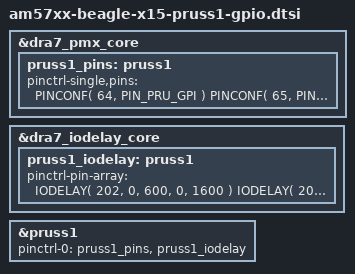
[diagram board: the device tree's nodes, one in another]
#include "dra7-pin-convenience.h"

&dra7_pmx_core {
	pruss1_pins: pruss1 {
		pinctrl-single,pins = <
			PINCONF(  64, PIN_PRU_GPI )  // P19.52 core 0 gpi  0
			PINCONF(  65, PIN_PRU_GPI )  // P19.45 core 0 gpi  1
			PINCONF(  66, PIN_PRU_GPI )  // P19.48 core 0 gpi  2
			PINCONF(  67, PIN_PRU_GPI )  // P19.53 core 0 gpi  3
			PINCONF(  68, PIN_PRU_GPI )  // P19.14 core 0 gpi  4
			PINCONF(  69, PIN_PRU_GPI )  // P19.15 core 0 gpi  5
			PINCONF(  71, PIN_PRU_GPI )  // P19.46 core 0 gpi  7
			PINCONF(  72, PIN_PRU_GPI )  // P19.49 core 0 gpi  8
			PINCONF(  73, PIN_PRU_GPI )  // P19.42 core 0 gpi  9
			PINCONF(  75, PIN_PRU_GPI )  // P19.43 core 0 gpi 11
			PINCONF(  77, PIN_PRU_GPI )  // P19.11 core 0 gpi 13
			PINCONF(  80, PIN_PRU_GPI )  // P19.39 core 0 gpi 16
			PINCONF(  81, PIN_PRU_GPI )  // P19.12 core 0 gpi 17
			PINCONF(  83, PIN_PRU_GPI )  // P19.40 core 0 gpi 19

			PINCONF(  93, PIN_PRU_GPI )  // P18.42 core 1 gpi  0
			PINCONF(  94, PIN_PRU_GPI )  // P18.13 core 1 gpi  1
			PINCONF(  95, PIN_PRU_GPI )  // P18.08 core 1 gpi  2
			PINCONF(  96, PIN_PRU_GPI )  // P18.43 core 1 gpi  3
			PINCONF(  97, PIN_PRU_GPI )  // P18.39 core 1 gpi  4
			PINCONF(  98, PIN_PRU_GPI )  // P18.38 core 1 gpi  5
			PINCONF(  99, PIN_PRU_GPI )  // P18.07 core 1 gpi  6
			PINCONF( 100, PIN_PRU_GPI )  // P18.44 core 1 gpi  7
			PINCONF( 101, PIN_PRU_GPI )  // P18.06 core 1 gpi  8
		>;
	};
};

&dra7_iodelay_core {
	pruss1_iodelay: pruss1 {
		pinctrl-pin-array = <
			IODELAY( 202, 0,  600, 0, 1600 )  // P19.52 core 0 gpio  0
			IODELAY( 203, 0,    0, 0, 2800 )  // P19.45 core 0 gpio  1
			IODELAY( 204, 0,  900, 0,    0 )  // P19.48 core 0 gpio  2
			IODELAY( 205, 0,  400, 0,    0 )  // P19.53 core 0 gpio  3
			IODELAY( 206, 0,  500, 0,    0 )  // P19.14 core 0 gpio  4
			IODELAY( 207, 0,    0, 0,    0 )  // P19.15 core 0 gpio  5
			IODELAY( 186, 0,    0, 0,  600 )  // P19.46 core 0 gpio  7
			IODELAY( 187, 0,  300, 0,    0 )  // P19.49 core 0 gpio  8
			IODELAY( 188, 0,  800, 0, 2700 )  // P19.42 core 0 gpio  9
			IODELAY( 190, 0,  600, 0,  800 )  // P19.43 core 0 gpio 11
			IODELAY( 192, 0,  800, 0,  100 )  // P19.11 core 0 gpio 13
			IODELAY( 195, 0, 2800, 0,  400 )  // P19.39 core 0 gpio 16
			IODELAY( 197, 0,  900, 0,  300 )  // P19.12 core 0 gpio 17
			IODELAY( 199, 0, 1400, 0,    0 )  // P19.40 core 0 gpio 19

			// note: 700ps common input delay removed
			IODELAY( 232, 0, 1400, 0, 3900 )  // P18.42 core 1 gpio  0
			IODELAY( 233, 0,  300, 0, 5100 )  // P18.13 core 1 gpio  1
			IODELAY( 234, 0, 1000, 0,    0 )  // P18.08 core 1 gpio  2
			IODELAY( 235, 0,    0, 0, 2700 )  // P18.43 core 1 gpio  3
			IODELAY( 236, 0,  600, 0, 2600 )  // P18.39 core 1 gpio  4
			IODELAY( 237, 0, 1000, 0, 2500 )  // P18.38 core 1 gpio  5
			IODELAY( 238, 0,  900, 0, 1900 )  // P18.07 core 1 gpio  6
			IODELAY( 216, 0,  900, 0, 1900 )  // P18.44 core 1 gpio  7
			IODELAY( 217, 0,  300, 0, 2700 )  // P18.06 core 1 gpio  8
		>;
	};
};

&pruss1 {
	pinctrl-names = "default";
	pinctrl-0 = <&pruss1_pins>, <&pruss1_iodelay>;
};
